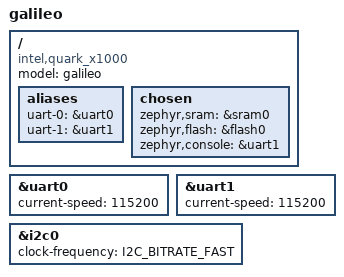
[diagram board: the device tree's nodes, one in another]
/dts-v1/;

#include <mem.h>

#define DT_FLASH_SIZE		DT_SIZE_K(1024)
#define DT_SRAM_SIZE		DT_SIZE_M(32)

#include <quark_x1000.dtsi>

/ {
	model = "galileo";
	compatible = "intel,quark_x1000";

	aliases {
		uart-0 = &uart0;
		uart-1 = &uart1;
	};

	chosen {
		zephyr,sram = &sram0;
		zephyr,flash = &flash0;
		zephyr,console = &uart1;
	};
};

&uart0 {
	status = "ok";
	current-speed = <115200>;
};

&uart1 {
	status = "ok";
	current-speed = <115200>;
};

&i2c0 {
	status = "ok";
	clock-frequency = <I2C_BITRATE_FAST>;
};
